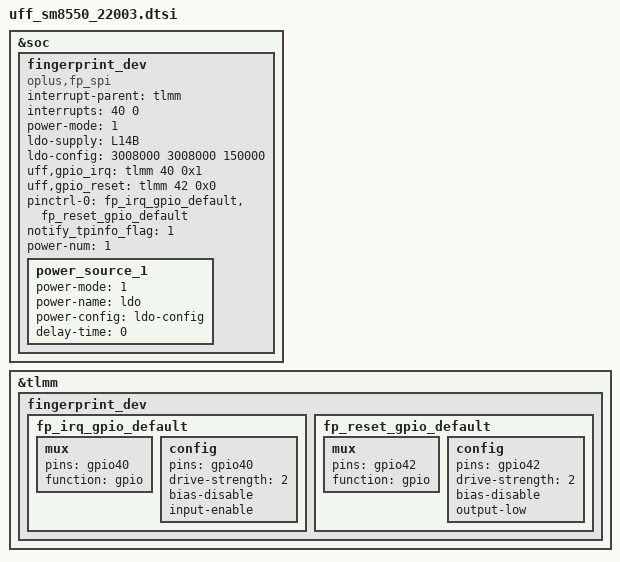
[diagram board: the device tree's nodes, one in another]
&soc {
	// #ifdef OPLUS_FEATURE_UFF_FINGERPRINT
	fingerprint_dev {
		status = "ok";
		compatible = "oplus,fp_spi";
		interrupt-parent = <&tlmm>;
		interrupts = <40 0>;
		power-mode = <1> ; /*0: power mode not set, 1: ldo power, 2: gpio power, 3: auto power */
		ldo-supply = <&L14B>;
		ldo-config = <3008000 3008000 150000>;
		uff,gpio_irq = <&tlmm 40 0x1>;
		uff,gpio_reset = <&tlmm 42 0x0>;
		pinctrl-names = "default";
		pinctrl-0 = <&fp_irq_gpio_default>,<&fp_reset_gpio_default>;
		notify_tpinfo_flag = <1>;
		power-num = <1>;
		power_source_1 {
			power-mode = <1>;
			power-name = "ldo";
			power-config = "ldo-config";
			delay-time = <0>;
		};
	};
	//#endif /*OPLUS_FEATURE_UFF_FINGERPRINT*/
};

&tlmm {
	// #ifdef OPLUS_FEATURE_UFF_FINGERPRINT
	fingerprint_dev{
		fp_irq_gpio_default: fp_irq_gpio_default {
			mux {
				pins = "gpio40";
				function = "gpio";
			};
			config {
				pins = "gpio40";
				drive-strength = <2>;
				bias-disable;
				input-enable;
			};
		};

		fp_reset_gpio_default: fp_reset_gpio_default {
			mux {
				pins = "gpio42";
				function = "gpio";
			};
			config {
				pins = "gpio42";
				drive-strength = <2>;
				bias-disable;
				output-low;
			};
		};
	};
	//#endif /*OPLUS_FEATURE_UFF_FINGERPRINT*/
};
